VERSION "1.0"

NS_ :

BS_:

BU_: ECU

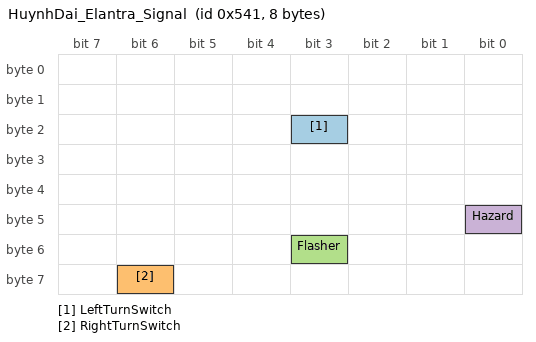
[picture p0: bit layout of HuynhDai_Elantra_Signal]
BO_ 1345 HuynhDai_Elantra_Signal: 8 ECU
    SG_ LeftTurnSwitch : 19|1@0+ (1,0) [0|1] "" ECU
    SG_ RightTurnSwitch : 62|1@0+ (1,0) [0|1] "" ECU
    SG_ Flasher : 51|1@0+ (1,0) [0|1] "" ECU
    SG_ Hazard : 40|1@0+ (1,0) [0|1] "" ECU

VAL_ 1345 LeftTurnSwitch 0 "OFF" 1 "ON";
VAL_ 1345 RightTurnSwitch 0 "OFF" 1 "ON";
VAL_ 1345 Flasher 0 "OFF" 1 "ON";
VAL_ 1345 Hazard 0 "OFF" 1 "ON";
